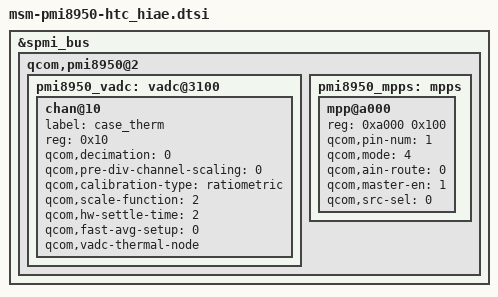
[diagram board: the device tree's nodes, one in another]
&spmi_bus {

	qcom,pmi8950@2 {
		pmi8950_vadc: vadc@3100 {
			chan@10 {
				label = "case_therm";
				reg = <0x10>;
				qcom,decimation = <0>;
				qcom,pre-div-channel-scaling = <0>;
				qcom,calibration-type = "ratiometric";
				qcom,scale-function = <2>;
				qcom,hw-settle-time = <2>;
				qcom,fast-avg-setup = <0>;
				qcom,vadc-thermal-node;
			};
		};
		pmi8950_mpps: mpps {
			mpp@a000 {
				/* MPP1 - HIAE CASE_THERM config */
				reg = <0xa000 0x100>;
				qcom,pin-num = <1>;
				qcom,mode = <4>; /* AIN input */
				qcom,ain-route = <0>; /* AMUX 5 */
				qcom,master-en = <1>; /* Enable MPP */
				qcom,src-sel = <0>; /* Function constant */
				status = "ok";
			};
		};
	};
};

